VERSION ""

NS_ :

BS_:

BU_: DAQ SBFront1 SBFront2 SBRear1 SBRear2 SBCG

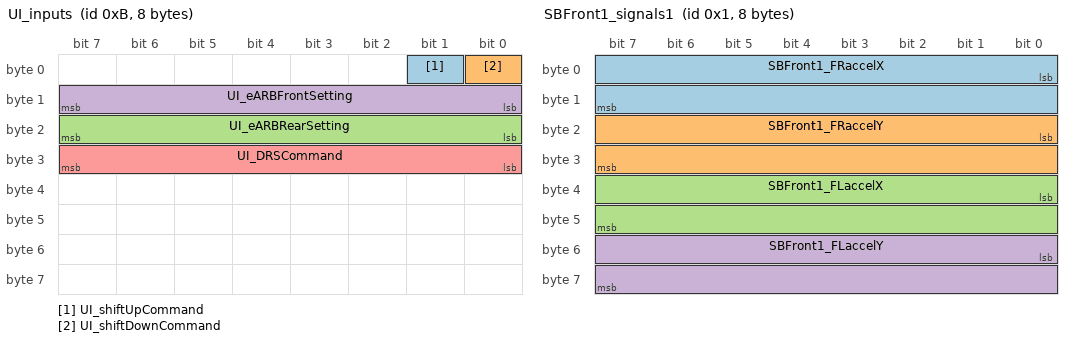
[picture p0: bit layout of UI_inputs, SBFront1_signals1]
BO_ 11 UI_inputs: 8 DAQ
 SG_ UI_shiftUpCommand : 1|1@1+ (1,0) [0|1] "" Vector__XXX
 SG_ UI_shiftDownCommand : 0|1@1+ (1,0) [0|1] "" Vector__XXX
 SG_ UI_eARBRearSetting : 16|8@1- (1,0) [-80|80] "deg" Vector__XXX
 SG_ UI_eARBFrontSetting : 8|8@1- (1,0) [-80|80] "deg" Vector__XXX
 SG_ UI_DRSCommand : 24|8@1- (1,0) [-80|80] "deg" Vector__XXX

BO_ 1 SBFront1_signals1: 8 SBFront1
 SG_ SBFront1_FRaccelX : 0|16@1+ (1,0) [0|0] ""  DAQ
 SG_ SBFront1_FRaccelY : 16|16@1+ (1,0) [0|0] ""  DAQ
 SG_ SBFront1_FLaccelX : 32|16@1+ (1,0) [0|0] ""  DAQ
 SG_ SBFront1_FLaccelY : 48|16@1+ (1,0) [0|0] ""  DAQ

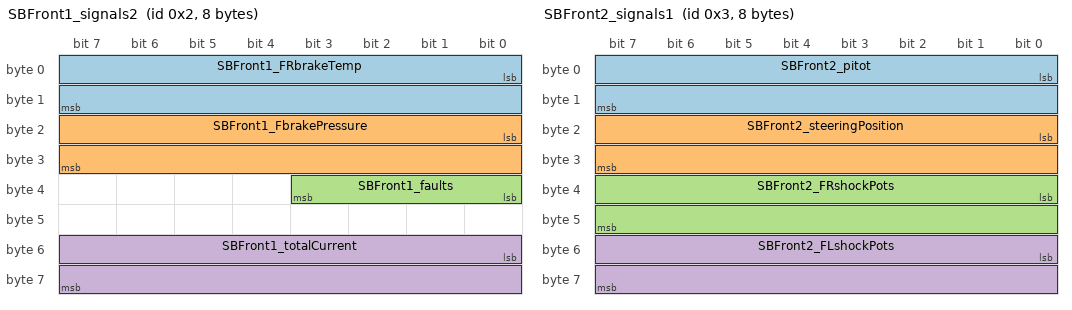
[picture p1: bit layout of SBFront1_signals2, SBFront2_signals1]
BO_ 2 SBFront1_signals2: 8 SBFront1
 SG_ SBFront1_FRbrakeTemp : 0|16@1+ (1,0) [0|0] ""  DAQ
 SG_ SBFront1_FbrakePressure : 16|16@1+ (1,0) [0|0] ""  DAQ
 SG_ SBFront1_faults : 32|4@1+ (1,0) [0|0] ""  DAQ
 SG_ SBFront1_totalCurrent : 48|16@1+ (6E-006,0) [0|0.39321] "A"  DAQ

BO_ 3 SBFront2_signals1: 8 SBFront2
 SG_ SBFront2_pitot : 0|16@1+ (1,0) [0|0] ""  DAQ
 SG_ SBFront2_steeringPosition : 16|16@1+ (1,0) [0|0] ""  DAQ
 SG_ SBFront2_FRshockPots : 32|16@1+ (1,0) [0|0] ""  DAQ
 SG_ SBFront2_FLshockPots : 48|16@1+ (1,0) [0|0] ""  DAQ

BO_ 4 SBFront2_signals2: 8 SBFront2
 SG_ SBFront2_faults : 32|4@1+ (1,0) [0|0] ""  DAQ
 SG_ SBFront2_totalCurrent : 40|18@1+ (1,0) [0|0] ""  DAQ

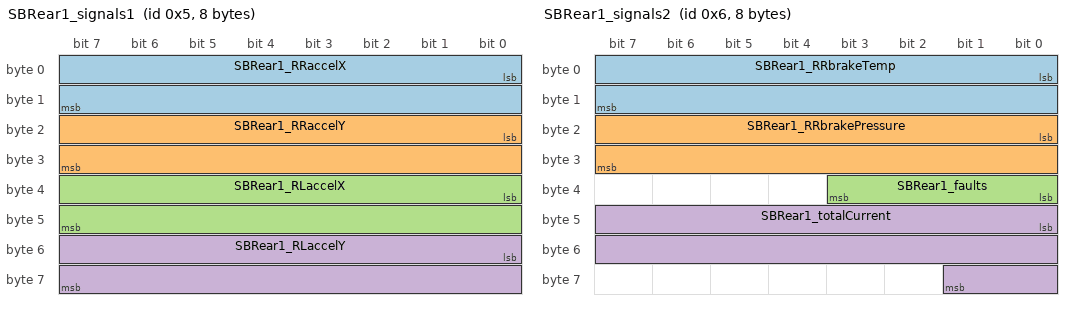
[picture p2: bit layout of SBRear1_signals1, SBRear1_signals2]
BO_ 5 SBRear1_signals1: 8 SBRear1
 SG_ SBRear1_RRaccelX : 0|16@1+ (1,0) [0|0] ""  DAQ
 SG_ SBRear1_RRaccelY : 16|16@1+ (1,0) [0|0] ""  DAQ
 SG_ SBRear1_RLaccelX : 32|16@1+ (1,0) [0|0] ""  DAQ
 SG_ SBRear1_RLaccelY : 48|16@1+ (1,0) [0|0] ""  DAQ

BO_ 6 SBRear1_signals2: 8 SBRear1
 SG_ SBRear1_RRbrakeTemp : 0|16@1+ (1,0) [0|0] ""  DAQ
 SG_ SBRear1_RRbrakePressure : 16|16@1+ (1,0) [0|0] ""  DAQ
 SG_ SBRear1_faults : 32|4@1+ (1,0) [0|0] ""  DAQ
 SG_ SBRear1_totalCurrent : 40|18@1+ (1,0) [0|0] ""  DAQ

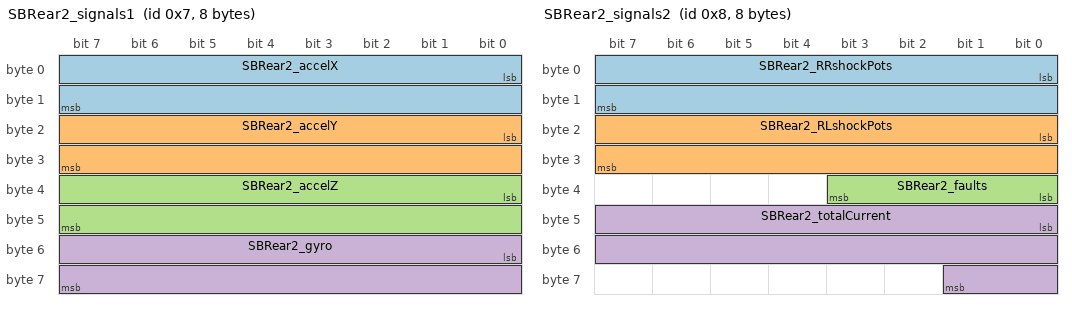
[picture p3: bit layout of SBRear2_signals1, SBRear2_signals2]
BO_ 7 SBRear2_signals1: 8 SBRear2
 SG_ SBRear2_accelX : 0|16@1+ (1,0) [0|0] ""  DAQ
 SG_ SBRear2_accelY : 16|16@1+ (1,0) [0|0] ""  DAQ
 SG_ SBRear2_accelZ : 32|16@1+ (1,0) [0|0] ""  DAQ
 SG_ SBRear2_gyro : 48|16@1+ (1,0) [0|0] ""  DAQ

BO_ 8 SBRear2_signals2: 8 SBRear2
 SG_ SBRear2_RRshockPots : 0|16@1+ (1,0) [0|0] ""  DAQ
 SG_ SBRear2_RLshockPots : 16|16@1+ (1,0) [0|0] ""  DAQ
 SG_ SBRear2_faults : 32|4@1+ (1,0) [0|0] ""  DAQ
 SG_ SBRear2_totalCurrent : 40|18@1+ (1,0) [0|0] ""  DAQ

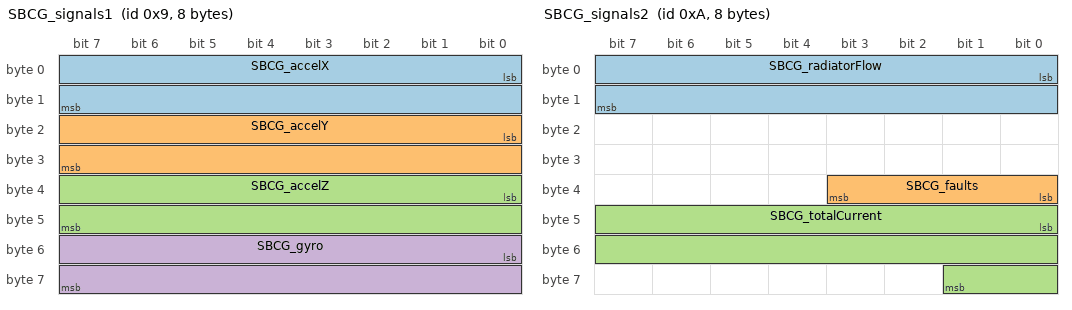
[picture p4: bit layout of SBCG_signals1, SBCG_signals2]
BO_ 9 SBCG_signals1: 8 SBCG
 SG_ SBCG_accelX : 0|16@1+ (1,0) [0|0] ""  DAQ
 SG_ SBCG_accelY : 16|16@1+ (1,0) [0|0] ""  DAQ
 SG_ SBCG_accelZ : 32|16@1+ (1,0) [0|0] ""  DAQ
 SG_ SBCG_gyro : 48|16@1+ (1,0) [0|0] ""  DAQ

BO_ 10 SBCG_signals2: 8 SBCG
 SG_ SBCG_radiatorFlow : 0|16@1+ (1,0) [0|0] ""  DAQ
 SG_ SBCG_faults : 32|4@1+ (1,0) [0|0] ""  DAQ
 SG_ SBCG_totalCurrent : 40|18@1+ (1,0) [0|0] ""  DAQ

CM_ BU_ DAQ "Dashboard Datalogger and Telemetry";
CM_ BU_ SBFront1 "Front sensor board 1";
CM_ BU_ SBFront2 "Front sensor board 2";
CM_ BU_ SBRear1 "Rear sensor board 1";
CM_ BU_ SBRear2 "Rear sensor board 2";
CM_ BU_ SBCG "Center of gravity sensor board";
BA_DEF_  "BusType" STRING ;
BA_DEF_ BO_  "GenMsgSendType" ENUM  "Cyclic";
BA_DEF_ BO_  "GenMsgCycleTime" INT 1 10000;
BA_DEF_DEF_  "BusType" "CAN";
BA_DEF_DEF_  "GenMsgSendType" "Cyclic";
BA_DEF_DEF_  "GenMsgCycleTime" 100;
BA_ "GenMsgCycleTime" BO_ 11 50;
BA_ "GenMsgCycleTime" BO_ 1 5;
BA_ "GenMsgCycleTime" BO_ 2 5;
BA_ "GenMsgCycleTime" BO_ 3 5;
BA_ "GenMsgCycleTime" BO_ 4 5;
BA_ "GenMsgCycleTime" BO_ 5 5;
BA_ "GenMsgCycleTime" BO_ 6 5;
BA_ "GenMsgCycleTime" BO_ 7 5;
BA_ "GenMsgCycleTime" BO_ 8 5;
BA_ "GenMsgCycleTime" BO_ 9 5;
BA_ "GenMsgCycleTime" BO_ 10 5;
